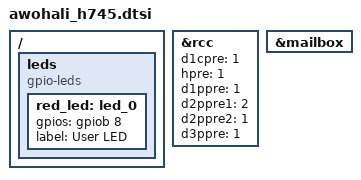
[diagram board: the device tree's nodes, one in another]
/*
 * Copyright (c) 2026 Madison Gleydura <deepspace00@pm.me>
 *
 * SPDX-License-Identifier: Apache-2.0
 */

#include <st/h7/stm32h745xihx-pinctrl.dtsi>
#include <zephyr/dt-bindings/input/input-event-codes.h>

/ {
	leds: leds {
		compatible = "gpio-leds";

		red_led: led_0 {
			gpios = <&gpiob 8 GPIO_ACTIVE_HIGH>;
			label = "User LED";
		};
	};
};

&rcc {
	d1cpre = <1>;
	hpre = <1>;
	d1ppre = <1>;
	d2ppre1 = <2>;
	d2ppre2 = <1>;
	d3ppre = <1>;
	status = "okay";
};

&mailbox {
	status = "okay";
};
